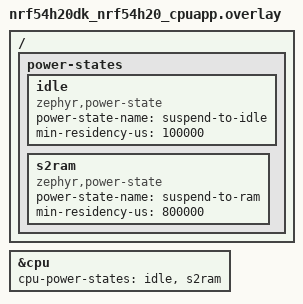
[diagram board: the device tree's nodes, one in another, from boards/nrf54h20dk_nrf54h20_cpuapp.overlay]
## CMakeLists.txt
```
# SPDX-License-Identifier: Apache-2.0

cmake_minimum_required(VERSION 3.20.0)

find_package(Zephyr REQUIRED HINTS $ENV{ZEPHYR_BASE})
project(hello_world)

target_sources(app PRIVATE src/main.c)

if(CONFIG_BOARD_FLIP_SIM_NRF54L15_CPUFLPR)
  target_sources(app PRIVATE src/flip_sim_printk.c)
  zephyr_linker_sources(ROM_START SORT_KEY 0x0vectors boards/flip_sim_nrf54l15_cpuflpr.ld)
endif()
```

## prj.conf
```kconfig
# nothing here
CONFIG_PM=y
CONFIG_PM_S2RAM=y
CONFIG_POWEROFF=y
CONFIG_PM_S2RAM_CUSTOM_MARKING=y
CONFIG_CONSOLE=n
CONFIG_UART_CONSOLE=n
CONFIG_SERIAL=n
CONFIG_GPIO=n
CONFIG_BOOT_BANNER=n
```

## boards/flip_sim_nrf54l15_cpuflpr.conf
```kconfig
# Copyright (c) 2026 Nordic Semiconductor ASA
# SPDX-License-Identifier: Apache-2.0

# FLIP prints via arch_printk_char_out trap (src/flip_sim_printk.c), not UARTE.
CONFIG_CONSOLE=y
CONFIG_STDOUT_CONSOLE=y
CONFIG_UART_CONSOLE=n
CONFIG_PRINTK=y
CONFIG_PM=y
CONFIG_PM_DEVICE=y
# UART00 remains available for future FLIP UARTE testing (optional).
# CONFIG_SERIAL=y
# CONFIG_UART_CONSOLE=y
```

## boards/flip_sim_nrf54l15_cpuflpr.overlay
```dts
/*
 * Copyright (c) 2026 Nordic Semiconductor ASA
 * SPDX-License-Identifier: Apache-2.0
 *
 * hello_world overlay for flip_sim/nrf54l15/cpuflpr (FLIP SystemC simulator).
 *
 * GRTC @ 0x400E2000 (NS) — kernel system clock / tick source in FLIP.
 * Console output uses the FLIP _sim_printk hook (startpc+0xA0), not UARTE.
 */

&grtc {
	/* Reserved for FLPR system counter (see nrf54l15dk cpuflpr). */
	owned-channels = <3 4>;
	clock-frequency = <1000000>;
	status = "okay";
};
```

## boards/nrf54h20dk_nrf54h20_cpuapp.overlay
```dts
/*
 * Copyright (c) 2023 Nordic Semiconductor ASA
 *
 * SPDX-License-Identifier: LicenseRef-BSD-5-Clause-Nordic
 */

/*
 * Copyright (c) 2024 Nordic Semiconductor ASA
 *
 * SPDX-License-Identifier: LicenseRef-Nordic-5-Clause
 */

/ {
    power-states {
        idle: idle {
            compatible = "zephyr,power-state";
            power-state-name = "suspend-to-idle";
            min-residency-us = <100000>;
        };

        s2ram: s2ram {
            compatible = "zephyr,power-state";
            power-state-name = "suspend-to-ram";
            min-residency-us = <800000>;
        };
    };
};

&cpu {
    cpu-power-states = <&idle &s2ram>;
};
```

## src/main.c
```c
/*
 * Copyright (c) 2012-2014 Wind River Systems, Inc.
 *
 * SPDX-License-Identifier: Apache-2.0
 */

#include <stdio.h>
#include <zephyr/kernel.h>
#include <hal/nrf_vpr_csr.h>

int main(void)
{
        csr_write(VPRCSR_NORDIC_VPRNORDICSLEEPCTRL,
                  VPRCSR_NORDIC_VPRNORDICSLEEPCTRL_SLEEPSTATE_WAIT);

	while(1) {
	    printf("What do we say to the god of death?\n");
	    printf("Not today zephyr: %s\n", CONFIG_BOARD_TARGET);
	    k_msleep(100);
        }	    

	return 0;
}
```

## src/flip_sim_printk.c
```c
/*
 * Copyright (c) 2026 Nordic Semiconductor ASA
 * SPDX-License-Identifier: Apache-2.0
 *
 * FLIP simulator console: arch_printk_char_out jumps to a trap at startpc+0xA0
 * (padding before the IRQ vector table). The simulator prints the character
 * from register a0 (x10) when PC hits that address (see flip/src/simulator.cpp).
 */

#include <stdint.h>
#include <zephyr/init.h>
#include <zephyr/sys/libc-hooks.h>
#include <zephyr/sys/printk-hooks.h>

#define FLIP_SIM_PRINTK_TRAP (0x30008000U + 0xA0U)

__attribute__((section(".flip_sim_hook"), used, naked))
void flip_sim_printk_trap(void)
{
	__asm__ volatile(
		".option push\n"
		".option norvc\n"
		"nop\n"
		"nop\n"
		"ret\n"
		".option pop\n");
}

int arch_printk_char_out(int c)
{
	__asm__ volatile(
		".option push\n"
		".option norvc\n"
		"mv a0, %0\n"
		"j %1\n"
		".option pop\n"
		:
		: "r"((unsigned char)c), "i"(FLIP_SIM_PRINTK_TRAP)
		: "a0", "memory");

	return c;
}

static int flip_sim_console_init(void)
{
	__stdout_hook_install(arch_printk_char_out);
	__printk_hook_install(arch_printk_char_out);

	return 0;
}

SYS_INIT(flip_sim_console_init, PRE_KERNEL_1, 0);
```
